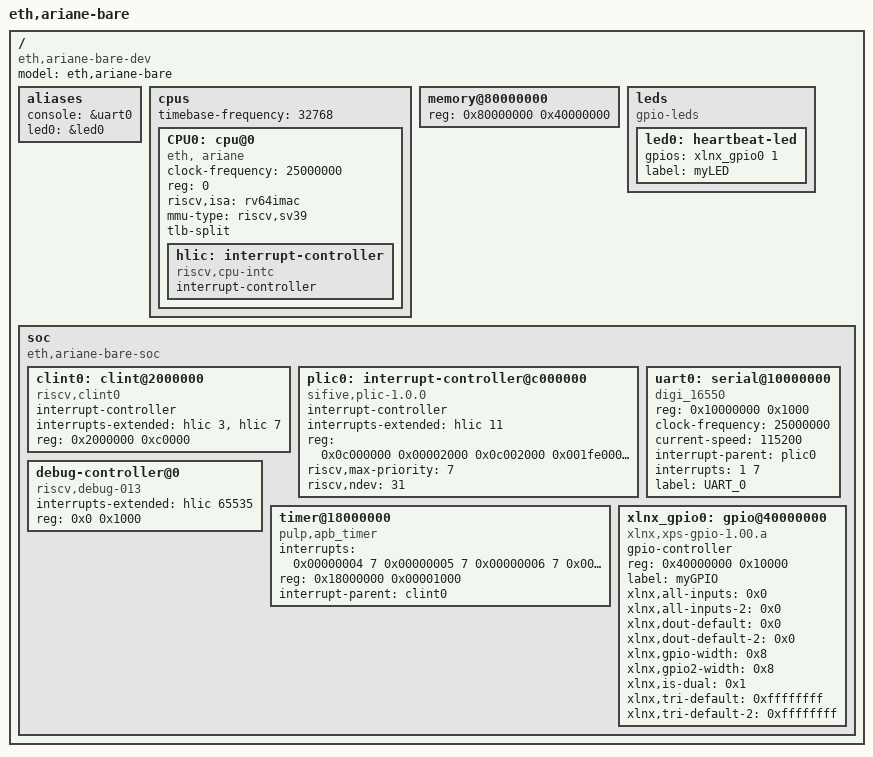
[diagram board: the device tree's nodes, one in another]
/dts-v1/;

/ {
    //#address-cells = <2>;
    //#size-cells = <2>;
    #address-cells = <1>;
    #size-cells = <1>;
    compatible = "eth,ariane-bare-dev";
    model = "eth,ariane-bare";

    aliases {
        console = &uart0;
        led0 = &led0;
    };
    
    cpus {
        #address-cells = <1>;
        #size-cells = <0>;
        timebase-frequency = <32768>; // 32.768 kHz
        CPU0: cpu@0 {
            clock-frequency = <25000000>; // 50 MHz
            device_type = "cpu";
            reg = <0>;
            status = "okay";
            compatible = "eth, ariane", "riscv";
            riscv,isa = "rv64imac";
            mmu-type = "riscv,sv39";
            tlb-split;
            
            hlic: interrupt-controller {
                #interrupt-cells = <1>;
                interrupt-controller;
                compatible = "riscv,cpu-intc";
            };
        };
    };

    memory@80000000 {
        device_type = "memory";
        reg = <0x80000000 0x40000000>;  // 1 Gbyte
    };


    leds {
        compatible = "gpio-leds";
        led0: heartbeat-led {
            gpios = <&xlnx_gpio0 1 0>;
            label = "myLED";
        };
    };

    soc {
        #address-cells = <1>;
        #size-cells = <1>;
        compatible = "eth,ariane-bare-soc", "simple-bus";
        ranges;
        clint0: clint@2000000 {
            #interrupt-cells = <1>;
            interrupt-controller;
            compatible = "riscv,clint0";
            interrupts-extended = <&hlic 3 &hlic 7>;
            reg = <0x2000000 0xc0000>;
            reg-names = "control";
        };

        plic0: interrupt-controller@c000000 {
            #interrupt-cells = <2>;
            compatible = "sifive,plic-1.0.0", "riscv,plic0-priority";
            interrupt-controller;
            interrupts-extended = <&hlic 11>;
            /*
             *  The first reg is the address of the PLIC_PRIO register, the 
             *  second entry being the length of said register.
             *  The next line is the IRQ_ENABLE offset followed by the context
             *  length. Finally followed by the claim register and the rest of
             *  the space.
             */
            reg = <0x0c000000 0x00002000
                   0x0c002000 0x001fe000
                   0x0c200000 0x03e00000>;
            reg-names = "prio", "irq_en", "reg";
            riscv,max-priority = <7>;
            riscv,ndev = <31>;
        };

        // TODO: How is this verified?
        debug-controller@0 {
            compatible = "riscv,debug-013";
            interrupts-extended = <&hlic 65535>;
            reg = <0x0 0x1000>;
            reg-names = "control";
        };

        uart0: serial@10000000 {
            compatible = "digi_16550", "uart0";
            reg = <0x10000000 0x1000>;
            clock-frequency = <25000000>;
            current-speed = <115200>;
            interrupt-parent = <&plic0>;
            interrupts = <1 7>;
            label = "UART_0";
            status = "okay";
        };

        timer@18000000 {
            compatible = "pulp,apb_timer";
            interrupts = <0x00000004 7 0x00000005 7 0x00000006 7 0x00000007 7>;
            reg = <0x18000000 0x00001000>;
            interrupt-parent = <&clint0>;
            reg-names = "control";
        };
        
        xlnx_gpio0: gpio@40000000 {
            #gpio-cells = <2>;
            compatible = "xlnx,xps-gpio-1.00.a";
            gpio-controller ;
            reg = <0x40000000 0x10000 >;
            label = "myGPIO";
            xlnx,all-inputs = <0x0>;
            xlnx,all-inputs-2 = <0x0>;
            xlnx,dout-default = <0x0>;
            xlnx,dout-default-2 = <0x0>;
            xlnx,gpio-width = <0x8>;
            xlnx,gpio2-width = <0x8>;
            xlnx,is-dual = <0x1>;
            xlnx,tri-default = <0xffffffff>;
            xlnx,tri-default-2 = <0xffffffff>;
        };
    }; // soc
};
